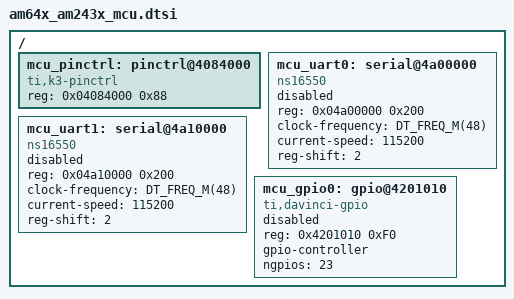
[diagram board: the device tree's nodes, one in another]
/*
 * Copyright (c) 2025 Texas Instruments Incorporated
 *
 * SPDX-License-Identifier: Apache-2.0
 */

#include <mem.h>
#include <freq.h>

/ {
  #address-cells = <1>;
  #size-cells = <1>;

	mcu_pinctrl: pinctrl@4084000 {
		compatible = "ti,k3-pinctrl";
		reg = <0x04084000 0x88>;
		status = "okay";
	};

  mcu_uart0: serial@4a00000 {
    compatible = "ns16550";
    reg = <0x04a00000 0x200>;
    clock-frequency = <DT_FREQ_M(48)>;
    current-speed = <115200>;
    reg-shift = <2>;
    status = "disabled";
  };

  mcu_uart1: serial@4a10000 {
    compatible = "ns16550";
    reg = <0x04a10000 0x200>;
    clock-frequency = <DT_FREQ_M(48)>;
    current-speed = <115200>;
    reg-shift = <2>;
    status = "disabled";
  };

  mcu_gpio0: gpio@4201010 {
    compatible = "ti,davinci-gpio";
    reg = <0x4201010 0xF0>;
    gpio-controller;
    #gpio-cells = <2>;
    ngpios = <23>;
    status = "disabled";
  };
};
